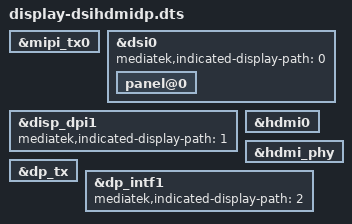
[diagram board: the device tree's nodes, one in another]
/dts-v1/;
/plugin/;

/ {
	fragment@0 {
		target = <&mipi_tx0>;
		__overlay__ {
			status = "okay";
		};
	};

	fragment@1 {
		target = <&dsi0>;
		__overlay__ {
			status = "okay";
			mediatek,indicated-display-path = <0>;
			panel@0 {
				status = "okay";
			};
		};
	};

	fragment@2 {
		target = <&disp_dpi1>;
		__overlay__ {
			status = "okay";
			mediatek,indicated-display-path = <1>;
		};
	};

	fragment@3 {
		target = <&hdmi0>;
		__overlay__ {
			status = "okay";
		};
	};

	fragment@4 {
		target = <&hdmi_phy>;
		__overlay__ {
			status = "okay";
		};
	};

	fragment@5 {
		target = <&dp_tx>;
		__overlay__ {
			status = "okay";
		};
	};

	fragment@6 {
		target = <&dp_intf1>;
		__overlay__ {
			status = "okay";
			mediatek,indicated-display-path = <2>;
		};
	};
};
